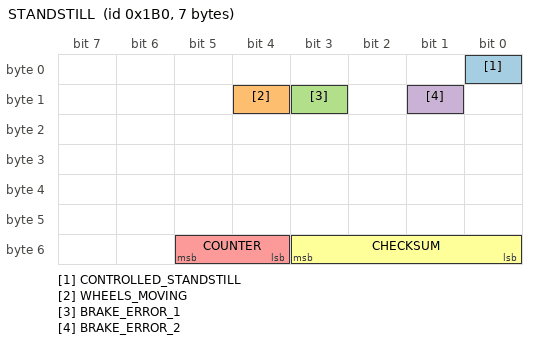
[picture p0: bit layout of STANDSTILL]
BO_ 432 STANDSTILL: 7 VSA
 SG_ CONTROLLED_STANDSTILL : 0|1@0+ (1,0) [0|1] "" EON
 SG_ WHEELS_MOVING : 12|1@0+ (1,0) [0|1] "" EON
 SG_ BRAKE_ERROR_1 : 11|1@0+ (1,0) [0|1] "" EON
 SG_ BRAKE_ERROR_2 : 9|1@0+ (1,0) [0|1] "" EON
 SG_ COUNTER : 53|2@0+ (1,0) [0|3] "" EON
 SG_ CHECKSUM : 51|4@0+ (1,0) [0|3] "" EON
